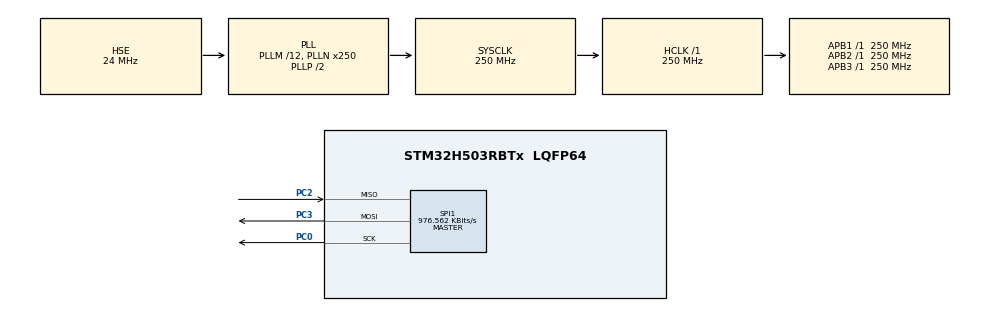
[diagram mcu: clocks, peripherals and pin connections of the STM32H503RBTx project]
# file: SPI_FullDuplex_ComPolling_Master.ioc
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Mcu.Family=STM32H5
Mcu.Name=STM32H503RBTx
Mcu.Package=LQFP64
NVIC.PriorityGroup=NVIC_PRIORITYGROUP_4
PC0.GPIO_PuPd=GPIO_PULLDOWN
PC0.GPIO_Speed=GPIO_SPEED_FREQ_VERY_HIGH
PC0.Mode=Full_Duplex_Master
PC0.Signal=SPI1_SCK
PC2.GPIO_PuPd=GPIO_PULLDOWN
PC2.GPIO_Speed=GPIO_SPEED_FREQ_VERY_HIGH
PC2.Mode=Full_Duplex_Master
PC2.Signal=SPI1_MISO
PC3.GPIO_PuPd=GPIO_PULLDOWN
PC3.GPIO_Speed=GPIO_SPEED_FREQ_VERY_HIGH
PC3.Mode=Full_Duplex_Master
PC3.Signal=SPI1_MOSI
PH0-OSC_IN(PH0).Mode=HSE-External-Oscillator
PH0-OSC_IN(PH0).Signal=RCC_OSC_IN
PH1-OSC_OUT(PH1).Mode=HSE-External-Oscillator
PH1-OSC_OUT(PH1).Signal=RCC_OSC_OUT
ProjectManager.HeapSize=0x200
ProjectManager.StackSize=0x400
ProjectManager.TargetToolchain=EWARM V9.20
RCC.ADCFreq_Value=250000000
RCC.AHBFreq_Value=250000000
RCC.APB1Freq_Value=250000000
RCC.APB1TimFreq_Value=250000000
RCC.APB2Freq_Value=250000000
RCC.APB2TimFreq_Value=250000000
RCC.APB3Freq_Value=250000000
RCC.CSI_VALUE=4000000
RCC.CortexFreq_Value=250000000
RCC.EPOD_VALUE=24000000
RCC.HCLKFreq_Value=250000000
RCC.HSE_VALUE=24000000
RCC.HSI48_VALUE=48000000
RCC.HSIDiv=RCC_HSI_DIV1
RCC.HSI_VALUE=64000000
RCC.LSE_VALUE=32768
RCC.LSIRC_VALUE=32000
RCC.PLLM=12
RCC.PLLN=250
RCC.PLLSourceVirtual=RCC_PLL1_SOURCE_HSE
RCC.SYSCLKFreq_VALUE=250000000
RCC.SYSCLKSource=RCC_SYSCLKSOURCE_PLLCLK
RCC.USBFreq_Value=48000000
RCC.VCOOutputFreq_Value=500000000
SPI1.BaudRatePrescaler=SPI_BAUDRATEPRESCALER_256
SPI1.CLKPhase=SPI_PHASE_1EDGE
SPI1.CLKPolarity=SPI_POLARITY_LOW
SPI1.CRCCalculation=SPI_CRCCALCULATION_DISABLE
SPI1.CalculateBaudRate=976.562 KBits/s
SPI1.DataSize=SPI_DATASIZE_16BIT
SPI1.Direction=SPI_DIRECTION_2LINES
SPI1.FirstBit=SPI_FIRSTBIT_MSB
SPI1.GPIO_SPEED=GPIO_SPEED_FREQ_HIGH
SPI1.Mode=SPI_MODE_MASTER
SPI1.NSS=SPI_NSS_SOFT
SPI1.NSSPMode=SPI_NSS_PULSE_ENABLE
SPI1.TIMode=SPI_TIMODE_DISABLE
SPI1.VirtualType=VM_MASTER
VP_ICACHE_VS_ICACHE.Mode=DefaultMode
VP_PWR_VS_SECSignals.Mode=Security/Privilege
board=custom

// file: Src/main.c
/* USER CODE BEGIN Header */
/**
  ******************************************************************************
  * @file    SPI/SPI_FullDuplex_ComPolling_Master/Src/main.c
  * @author  MCD Application Team
  * @brief   This sample code shows how to use STM32H5xx SPI HAL API to transmit
  *          and receive a data buffer with a communication process based on
  *          Polling transfer.
  *          The communication is done using 2 Boards.
  ******************************************************************************
  * @attention
  *
  * Copyright (c) 2023 STMicroelectronics.
  * All rights reserved.
  *
  * This software is licensed under terms that can be found in the LICENSE file
  * in the root directory of this software component.
  * If no LICENSE file comes with this software, it is provided AS-IS.
  *
  ******************************************************************************
  */
/* USER CODE END Header */
#include "main.h"

SPI_HandleTypeDef hspi1;

/* USER CODE BEGIN PV */
/* Buffer used for transmission */
uint16_t aTxBuffer[] = {0x1234,0x5678,0x9ABC,0xDEF0,0x1234,0x5678,0x9ABC,0xDEF0,0x1234,0x5678,0x9ABC,0xDEF0,0x1234,0x5678,0x9ABC,0xDEF0,0x1234,0x5678,0x9ABC,0xDEF0,0x1234,0x5678,0x9ABC,0xDEF0,0x1234,0x5678,0x9ABC,0xDEF0,0x1234,0x5678,0x9ABC,0xDEF0,0x1234,0x5678,0x9ABC,0xDEF0,0x1234,0x5678,0x9ABC,0xDEF0};
__IO uint16_t ubNbDataToTransmit = BUFFERSIZE;
__IO uint8_t ubTransmitIndex = 0;

/* Buffer used for reception */
uint16_t aRxBuffer[BUFFERSIZE];
__IO uint16_t ubNbDataToReceive = BUFFERSIZE;
__IO uint8_t ubReceiveIndex = 0;
/* USER CODE END PV */

void SystemClock_Config(void);
static void MX_GPIO_Init(void);
static void MX_SPI1_Init(void);
static void MX_ICACHE_Init(void);
/* USER CODE BEGIN PFP */
static uint16_t Buffercmp(uint8_t *pBuffer1, uint8_t *pBuffer2, uint16_t BufferLength);

/* USER CODE END PFP */

int main(void)
{

  /* USER CODE BEGIN 1 */

  /* STM32H5xx HAL library initialization:
       - Systick timer is configured by default as source of time base, but user
             can eventually implement his proper time base source (a general purpose
             timer for example or other time source), keeping in mind that Time base
             duration should be kept 1ms since PPP_TIMEOUT_VALUEs are defined and
             handled in milliseconds basis.
       - Set NVIC Group Priority to 4
       - Low Level Initialization
     */
  /* USER CODE END 1 */

  /* MCU Configuration--------------------------------------------------------*/

  /* Reset of all peripherals, Initializes the Flash interface and the Systick. */
  HAL_Init();

  /* Configure the system clock */
  SystemClock_Config();

  /* Initialize all configured peripherals */
  MX_GPIO_Init();
  MX_SPI1_Init();
  MX_ICACHE_Init();
  /* USER CODE BEGIN 2 */

  /* Configure LED2 */
  BSP_LED_Init(LED2);

  /* Configure USER push-button button */
  BSP_PB_Init(BUTTON_USER, BUTTON_MODE_GPIO);

  /* Wait for USER push-button press before starting the Communication */
  while (BSP_PB_GetState(BUTTON_USER) != GPIO_PIN_SET)
  {
    BSP_LED_Toggle(LED2);
    HAL_Delay(100);
  }
  BSP_LED_Off(LED2);

  /*##-1- Start the Full Duplex Communication process ########################*/
  /* Enable SPI before start transmission */
  LL_SPI_Enable(hspi1.Instance);

  LL_SPI_StartMasterTransfer(hspi1.Instance);

  while(ubNbDataToReceive > 0)
  {
    /* Check TXP flag to transmit data */
    if(( LL_SPI_IsActiveFlag_TXP(hspi1.Instance)) && (ubNbDataToTransmit > 0))
    {
      /* Transmit 16bit Data */
      LL_SPI_TransmitData16(hspi1.Instance, aTxBuffer[ubTransmitIndex++]);
      ubNbDataToTransmit--;
    }
    /* Check RXP flag */
    if(LL_SPI_IsActiveFlag_RXP(hspi1.Instance))
    {
      /* Receive 16bit Data */
      aRxBuffer[ubReceiveIndex++] = LL_SPI_ReceiveData16(hspi1.Instance);
      ubNbDataToReceive--;
    }
    HAL_Delay(1);
  }

  /*##-3- Compare the sent and received buffers ##############################*/
  /* Compare the sent and received buffers */
  if (Buffercmp((uint8_t *)aTxBuffer, (uint8_t *)aRxBuffer, COUNTOF(aTxBuffer)))
  {
    /* Transfer error in transmission process */
    Error_Handler();
  }
  else
  {
    /* Turn LED2 on: Transfer in transmission/Reception process is correct */
    BSP_LED_On(LED2);
  }
  /* USER CODE END 2 */

  /* Infinite loop */
  while (1)
  {

  }
}

void SystemClock_Config(void)
{
  RCC_OscInitTypeDef RCC_OscInitStruct = {0};
  RCC_ClkInitTypeDef RCC_ClkInitStruct = {0};

  /** Configure the main internal regulator output voltage
  */
  __HAL_PWR_VOLTAGESCALING_CONFIG(PWR_REGULATOR_VOLTAGE_SCALE0);

  while(!__HAL_PWR_GET_FLAG(PWR_FLAG_VOSRDY)) {}

  /** Initializes the RCC Oscillators according to the specified parameters
  * in the RCC_OscInitTypeDef structure.
  */
  RCC_OscInitStruct.OscillatorType = RCC_OSCILLATORTYPE_HSE;
  RCC_OscInitStruct.HSEState = RCC_HSE_ON;
  RCC_OscInitStruct.PLL.PLLState = RCC_PLL_ON;
  RCC_OscInitStruct.PLL.PLLSource = RCC_PLL1_SOURCE_HSE;
  RCC_OscInitStruct.PLL.PLLM = 12;
  RCC_OscInitStruct.PLL.PLLN = 250;
  RCC_OscInitStruct.PLL.PLLP = 2;
  RCC_OscInitStruct.PLL.PLLQ = 2;
  RCC_OscInitStruct.PLL.PLLR = 2;
  RCC_OscInitStruct.PLL.PLLRGE = RCC_PLL1_VCIRANGE_1;
  RCC_OscInitStruct.PLL.PLLVCOSEL = RCC_PLL1_VCORANGE_WIDE;
  RCC_OscInitStruct.PLL.PLLFRACN = 0;
  if (HAL_RCC_OscConfig(&RCC_OscInitStruct) != HAL_OK)
  {
    Error_Handler();
  }

  /** Initializes the CPU, AHB and APB buses clocks
  */
  RCC_ClkInitStruct.ClockType = RCC_CLOCKTYPE_HCLK|RCC_CLOCKTYPE_SYSCLK
                              |RCC_CLOCKTYPE_PCLK1|RCC_CLOCKTYPE_PCLK2
                              |RCC_CLOCKTYPE_PCLK3;
  RCC_ClkInitStruct.SYSCLKSource = RCC_SYSCLKSOURCE_PLLCLK;
  RCC_ClkInitStruct.AHBCLKDivider = RCC_SYSCLK_DIV1;
  RCC_ClkInitStruct.APB1CLKDivider = RCC_HCLK_DIV1;
  RCC_ClkInitStruct.APB2CLKDivider = RCC_HCLK_DIV1;
  RCC_ClkInitStruct.APB3CLKDivider = RCC_HCLK_DIV1;

  if (HAL_RCC_ClockConfig(&RCC_ClkInitStruct, FLASH_LATENCY_5) != HAL_OK)
  {
    Error_Handler();
  }

  /** Configure the programming delay
  */
  __HAL_FLASH_SET_PROGRAM_DELAY(FLASH_PROGRAMMING_DELAY_2);
}

static void MX_ICACHE_Init(void)
{

  /** Enable instruction cache (default 2-ways set associative cache)
  */
  if (HAL_ICACHE_Enable() != HAL_OK)
  {
    Error_Handler();
  }

}

static void MX_SPI1_Init(void)
{

  /* SPI1 parameter configuration*/
  hspi1.Instance = SPI1;
  hspi1.Init.Mode = SPI_MODE_MASTER;
  hspi1.Init.Direction = SPI_DIRECTION_2LINES;
  hspi1.Init.DataSize = SPI_DATASIZE_16BIT;
  hspi1.Init.CLKPolarity = SPI_POLARITY_LOW;
  hspi1.Init.CLKPhase = SPI_PHASE_1EDGE;
  hspi1.Init.NSS = SPI_NSS_SOFT;
  hspi1.Init.BaudRatePrescaler = SPI_BAUDRATEPRESCALER_256;
  hspi1.Init.FirstBit = SPI_FIRSTBIT_MSB;
  hspi1.Init.TIMode = SPI_TIMODE_DISABLE;
  hspi1.Init.CRCCalculation = SPI_CRCCALCULATION_DISABLE;
  hspi1.Init.CRCPolynomial = 0x7;
  hspi1.Init.NSSPMode = SPI_NSS_PULSE_ENABLE;
  hspi1.Init.NSSPolarity = SPI_NSS_POLARITY_LOW;
  hspi1.Init.FifoThreshold = SPI_FIFO_THRESHOLD_01DATA;
  hspi1.Init.MasterSSIdleness = SPI_MASTER_SS_IDLENESS_00CYCLE;
  hspi1.Init.MasterInterDataIdleness = SPI_MASTER_INTERDATA_IDLENESS_00CYCLE;
  hspi1.Init.MasterReceiverAutoSusp = SPI_MASTER_RX_AUTOSUSP_DISABLE;
  hspi1.Init.MasterKeepIOState = SPI_MASTER_KEEP_IO_STATE_DISABLE;
  hspi1.Init.IOSwap = SPI_IO_SWAP_DISABLE;
  hspi1.Init.ReadyMasterManagement = SPI_RDY_MASTER_MANAGEMENT_INTERNALLY;
  hspi1.Init.ReadyPolarity = SPI_RDY_POLARITY_HIGH;
  if (HAL_SPI_Init(&hspi1) != HAL_OK)
  {
    Error_Handler();
  }

}

static void MX_GPIO_Init(void)
{

  /* GPIO Ports Clock Enable */
  __HAL_RCC_GPIOH_CLK_ENABLE();
  __HAL_RCC_GPIOC_CLK_ENABLE();

}

/* USER CODE BEGIN 4 */

/**
  * @brief  Compares two buffers.
  * @param  pBuffer1, pBuffer2: buffers to be compared.
  * @param  BufferLength: buffer's length
  * @retval 0  : pBuffer1 identical to pBuffer2
  *         >0 : pBuffer1 differs from pBuffer2
  */
static uint16_t Buffercmp(uint8_t* pBuffer1, uint8_t* pBuffer2, uint16_t BufferLength)
{
  while (BufferLength--)
  {
    if((*pBuffer1) != *pBuffer2)
    {
      return BufferLength;
    }
    pBuffer1++;
    pBuffer2++;
  }

  return 0;
}

/* USER CODE END 4 */

void Error_Handler(void)
{
  /* USER CODE BEGIN Error_Handler_Debug */
  /* User can add his own implementation to report the HAL error return state */
  while(1)
  {
    /* Toggle LED2 for error */
    BSP_LED_Toggle(LED2);
    HAL_Delay(1000);
  }
  /* USER CODE END Error_Handler_Debug */
}
